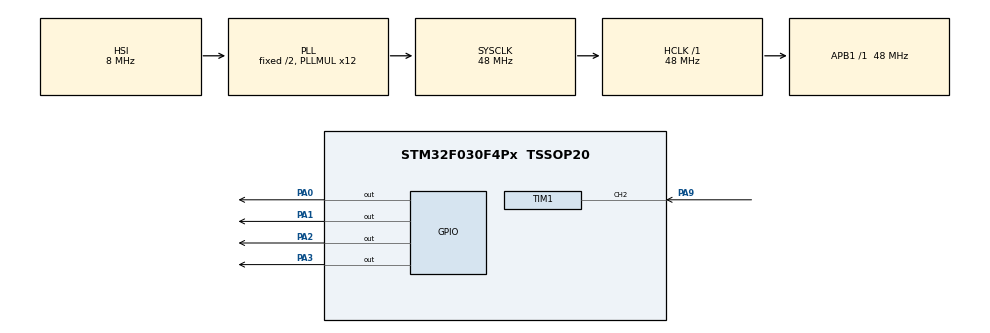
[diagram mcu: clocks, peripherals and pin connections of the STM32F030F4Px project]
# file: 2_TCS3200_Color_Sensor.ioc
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Mcu.Family=STM32F0
RCC.SYSCLKSource=RCC_SYSCLKSOURCE_PLLCLK
ProjectManager.StackSize=0x400
PA13.Signal=SYS_SWDIO
TIM1.Prescaler=47
ProjectManager.TargetToolchain=STM32CubeIDE
RCC.HCLKFreq_Value=48000000
PA9.Signal=S_TIM1_CH2
PA1.Signal=GPIO_Output
RCC.AHBFreq_Value=48000000
PF0-OSC_IN.Mode=HSE-External-Oscillator
board=custom
RCC.PLLMUL=RCC_PLL_MUL12
SH.S_TIM1_CH2.0=TIM1_CH2,Input_Capture2_from_TI2
PA14.Mode=Serial_Wire
PA13.Mode=Serial_Wire
Mcu.Name=STM32F030F4Px
TIM1.Channel-Input_Capture2_from_TI2=TIM_CHANNEL_2
VP_TIM1_VS_ClockSourceINT.Mode=Internal
PA2.Signal=GPIO_Output
PA0.Signal=GPIO_Output
NVIC.TIM1_CC_IRQn=true\:0\:0\:false\:false\:true\:true\:true
RCC.SYSCLKFreq_VALUE=48000000
Mcu.Package=TSSOP20
PA14.Signal=SYS_SWCLK
ProjectManager.HeapSize=0x200
TIM1.ICPolarity_CH2=TIM_INPUTCHANNELPOLARITY_FALLING
RCC.APB1TimFreq_Value=48000000
TIM1.Period=0xffff-1
PF0-OSC_IN.Signal=RCC_OSC_IN
PF1-OSC_OUT.Mode=HSE-External-Oscillator
RCC.APB1Freq_Value=48000000
PF1-OSC_OUT.Signal=RCC_OSC_OUT
PA3.Signal=GPIO_Output

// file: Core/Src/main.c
/* USER CODE BEGIN Header */
/**
  ******************************************************************************
  * @file           : main.c
  * @brief          : Main program body
  ******************************************************************************
  * @attention
  *
  * <h2><center>&copy; Copyright (c) 2021 STMicroelectronics.
  * All rights reserved.</center></h2>
  *
  * This software component is licensed by ST under BSD 3-Clause license,
  * the "License"; You may not use this file except in compliance with the
  * License. You may obtain a copy of the License at:
  *                        opensource.org/licenses/BSD-3-Clause
  *
  ******************************************************************************
  */
/* USER CODE END Header */
#include "main.h"

/* USER CODE BEGIN Includes */
#include "TCS3200.h"
/* USER CODE END Includes */

TIM_HandleTypeDef htim1;

void SystemClock_Config(void);
static void MX_GPIO_Init(void);
static void MX_TIM1_Init(void);

int main(void)
{

  /* MCU Configuration--------------------------------------------------------*/

  /* Reset of all peripherals, Initializes the Flash interface and the Systick. */
  HAL_Init();

  /* Configure the system clock */
  SystemClock_Config();

  /* Initialize all configured peripherals */
  MX_GPIO_Init();
  MX_TIM1_Init();
  /* USER CODE BEGIN 2 */
 // HAL_TIM_IC_Start_IT(&htim1, TIM_CHANNEL_2);
  tcs3200_freq(TCS3200_FREQ_2);
  tcs3200_switchColor(RED);
	//HAL_TIM_IC_Start_IT(&htim1, TIM_CHANNEL_2);
  uint32_t ff = tcs3200_getPulseFreq(htim1,TIM_CHANNEL_2);
  /* USER CODE END 2 */

  /* Infinite loop */
  while (1)
  {

    /* USER CODE BEGIN 3 */
	//  uint32_t ff = tcs3200_getPulseFreq(htim1,TIM_CHANNEL_2);
	  for(int i = 0; i<3;i++)
	  {
		  tcs3200_switchColor(i);
		  ff = tcs3200_getPulseFreq(htim1,TIM_CHANNEL_2);
		  HAL_Delay(1000);
	  }
  }
  /* USER CODE END 3 */
}

void SystemClock_Config(void)
{
  RCC_OscInitTypeDef RCC_OscInitStruct = {0};
  RCC_ClkInitTypeDef RCC_ClkInitStruct = {0};

  /** Initializes the RCC Oscillators according to the specified parameters
  * in the RCC_OscInitTypeDef structure.
  */
  RCC_OscInitStruct.OscillatorType = RCC_OSCILLATORTYPE_HSI;
  RCC_OscInitStruct.HSIState = RCC_HSI_ON;
  RCC_OscInitStruct.HSICalibrationValue = RCC_HSICALIBRATION_DEFAULT;
  RCC_OscInitStruct.PLL.PLLState = RCC_PLL_ON;
  RCC_OscInitStruct.PLL.PLLSource = RCC_PLLSOURCE_HSI;
  RCC_OscInitStruct.PLL.PLLMUL = RCC_PLL_MUL12;
  RCC_OscInitStruct.PLL.PREDIV = RCC_PREDIV_DIV1;
  if (HAL_RCC_OscConfig(&RCC_OscInitStruct) != HAL_OK)
  {
    Error_Handler();
  }
  /** Initializes the CPU, AHB and APB buses clocks
  */
  RCC_ClkInitStruct.ClockType = RCC_CLOCKTYPE_HCLK|RCC_CLOCKTYPE_SYSCLK
                              |RCC_CLOCKTYPE_PCLK1;
  RCC_ClkInitStruct.SYSCLKSource = RCC_SYSCLKSOURCE_PLLCLK;
  RCC_ClkInitStruct.AHBCLKDivider = RCC_SYSCLK_DIV1;
  RCC_ClkInitStruct.APB1CLKDivider = RCC_HCLK_DIV1;

  if (HAL_RCC_ClockConfig(&RCC_ClkInitStruct, FLASH_LATENCY_1) != HAL_OK)
  {
    Error_Handler();
  }
}

static void MX_TIM1_Init(void)
{

  TIM_ClockConfigTypeDef sClockSourceConfig = {0};
  TIM_MasterConfigTypeDef sMasterConfig = {0};
  TIM_IC_InitTypeDef sConfigIC = {0};

  htim1.Instance = TIM1;
  htim1.Init.Prescaler = 47;
  htim1.Init.CounterMode = TIM_COUNTERMODE_UP;
  htim1.Init.Period = 0xffff-1;
  htim1.Init.ClockDivision = TIM_CLOCKDIVISION_DIV1;
  htim1.Init.RepetitionCounter = 0;
  htim1.Init.AutoReloadPreload = TIM_AUTORELOAD_PRELOAD_DISABLE;
  if (HAL_TIM_Base_Init(&htim1) != HAL_OK)
  {
    Error_Handler();
  }
  sClockSourceConfig.ClockSource = TIM_CLOCKSOURCE_INTERNAL;
  if (HAL_TIM_ConfigClockSource(&htim1, &sClockSourceConfig) != HAL_OK)
  {
    Error_Handler();
  }
  if (HAL_TIM_IC_Init(&htim1) != HAL_OK)
  {
    Error_Handler();
  }
  sMasterConfig.MasterOutputTrigger = TIM_TRGO_RESET;
  sMasterConfig.MasterSlaveMode = TIM_MASTERSLAVEMODE_DISABLE;
  if (HAL_TIMEx_MasterConfigSynchronization(&htim1, &sMasterConfig) != HAL_OK)
  {
    Error_Handler();
  }
  sConfigIC.ICPolarity = TIM_INPUTCHANNELPOLARITY_FALLING;
  sConfigIC.ICSelection = TIM_ICSELECTION_DIRECTTI;
  sConfigIC.ICPrescaler = TIM_ICPSC_DIV1;
  sConfigIC.ICFilter = 0;
  if (HAL_TIM_IC_ConfigChannel(&htim1, &sConfigIC, TIM_CHANNEL_2) != HAL_OK)
  {
    Error_Handler();
  }

}

static void MX_GPIO_Init(void)
{
  GPIO_InitTypeDef GPIO_InitStruct = {0};

  /* GPIO Ports Clock Enable */
  __HAL_RCC_GPIOF_CLK_ENABLE();
  __HAL_RCC_GPIOA_CLK_ENABLE();

  /*Configure GPIO pin Output Level */
  HAL_GPIO_WritePin(GPIOA, GPIO_PIN_0|GPIO_PIN_1|GPIO_PIN_2|GPIO_PIN_3, GPIO_PIN_RESET);

  /*Configure GPIO pins : PA0 PA1 PA2 PA3 */
  GPIO_InitStruct.Pin = GPIO_PIN_0|GPIO_PIN_1|GPIO_PIN_2|GPIO_PIN_3;
  GPIO_InitStruct.Mode = GPIO_MODE_OUTPUT_PP;
  GPIO_InitStruct.Pull = GPIO_NOPULL;
  GPIO_InitStruct.Speed = GPIO_SPEED_FREQ_LOW;
  HAL_GPIO_Init(GPIOA, &GPIO_InitStruct);

}

void Error_Handler(void)
{
  __disable_irq();
  while (1)
  {
  }
}

/************************ (C) COPYRIGHT STMicroelectronics *****END OF FILE****/
